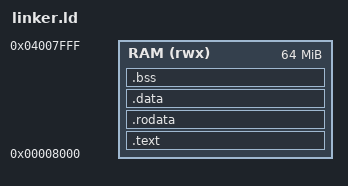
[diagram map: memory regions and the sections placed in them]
ENTRY(_start)

MEMORY
{
    RAM (rwx) : ORIGIN = 0x8000, LENGTH = 64M   /* Endereço inicial do Pi 2 */
}

SECTIONS
{
    .text : {
        *(.text*)
    } > RAM

    .rodata : {
        *(.rodata*)
    } > RAM

    .data : {
        *(.data*)
    } > RAM

    .bss (NOLOAD) : {
        __bss_start = .;
        *(.bss*)
        *(COMMON)
        __bss_end = .;
    } > RAM

    /* Heap começa logo após bss */
    __end = .;
}
